# H3 register map
Vendor: Allwinner; Series: H3; File version: 0.1
CPU: 0, little endian, MPU, no FPU, 0 interrupt priority bits
Registers are 32-bit, read-write, reset 0x0 unless marked. A register's access mark holds for its fields unless they carry their own. Offsets are from the block's base; [hi:lo] are bit positions; lines under a group give offsets from that group; {n}, {i} and the like mark numbered series; 'fields as' and 'values as' point back to an identical list; <NAME> marks a mode.

## AC
Base 0x01C22C00
0x00 AC group
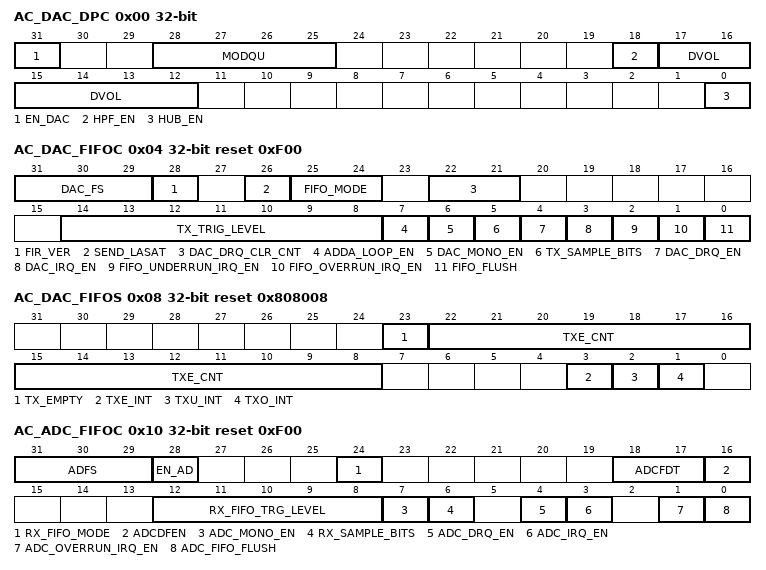
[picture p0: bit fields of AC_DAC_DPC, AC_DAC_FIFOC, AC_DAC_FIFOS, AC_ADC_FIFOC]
  0x00 AC_DAC_DPC — DAC Digital Part Control Register
    [31] EN_DAC — DAC Digital Part Enable 0 : Disable 1 : Enable
    [28:25] MODQU — Internal DAC Quantization Levels Levels=[7*(21+MODQU[3:0])]/128 Default levels=7*21/128=1.15
    [18] HPF_EN — High Pass Filter Enable 0: Disable 1: Enable
      0=Disable; 1=Enable
    [17:12] DVOL — Digital volume control: DVC, ATT=DVC[5:0]*(-1.16Db) 64 steps, -1.16Db/step
    [0] HUB_EN — Audio Hub Enable 0: Disable 1: Enable
      0=Disable; 1=Enable
  0x04 AC_DAC_FIFOC reset 0xF00 — DAC FIFO Control Register
    [31:29] DAC_FS — Sample Rate Of DAC 000: 48KHz 010: 24KHz 100: 12KHz 110: 192KHz 001: 32KHz 011: 16KHz 101: 8KHz 111: 96KHz 44.1KHz/22.05KHz/11.025KHz can be supported by Audio PLL Configure Bit
      0=_48KHz; 2=_24KHz; 4=_12KHz; 6=_192KHz; 1=_32KHz; 3=_16KHz; 5=_8KHz; 7=96KHz 44.1KHz/22.05KHz/11.025KHz can be supported by Audio PLL Configure Bit
    [28] FIR_VER — FIR Version 0: 64-Tap FIR; 1: 32-Tap FIR
      0=_64_minus_Tap (64-Tap FIR; 1: 32-Tap FIR)
    [26] SEND_LASAT — Audio sample select when TX FIFO under run 0: Sending zero 1: Sending last audio sample
      0=Sending_zero; 1=Sending last audio sample
    [25:24] FIFO_MODE — For 24-bits transmitted audio sample: 00/10: FIFO_I[23:0] = {TXDATA[31:8]} 01/11: Reserved For 16-bits transmitted audio sample: 00/10: FIFO_I[23:0] = {TXDATA[31:16], 8`b0} 01/11: FIFO_I[23:0] = {TXDATA[15:0], 8`b0}
    [22:21] DAC_DRQ_CLR_CNT — When TX FIFO Available Room Less Than Or Equal N, DRQ Request Will Be De-Asserted. N Is Defined Here: 00: IRQ/DRQ De-Asserted When WLEVEL > TXTL 01: 4 10: 8 11: 16
      0=IRQ_slash_DRQ (IRQ/DRQ De-Asserted When WLEVEL > TXTL); 1=_4; 2=_8; 3=_16
    [14:8] TX_TRIG_LEVEL — TX FIFO Empty Trigger Level (TXTL[12:0]) Interrupt and DMA request trigger level for TX FIFO normal condition. IRQ/DRQ Generated when WLEVEL <= TXTL Notes: 1. WLEVEL represents the number of valid samples in the TX FIFO 2. Only TXTL[6:0] valid when TXMODE = 0
    [7] ADDA_LOOP_EN — ADDA Loop Enable 0: Disable 1: Enable
      0=Disable; 1=Enable
    [6] DAC_MONO_EN — DAC Mono Enable 0: Stereo, 64 Levels FIFO 1: Mono, 128 Levels FIFO When Enabled, L & R Channel Send Same Data
      0=Stereo, 64 Levels FIFO; 1=Mono, 128 Levels FIFO When Enabled, L & R Channel Send Same Data
    [5] TX_SAMPLE_BITS — Transmitting Audio Sample Resolution 0: 16 bits 1: 24 bits
      0=_16_bits; 1=_24_bits
    [4] DAC_DRQ_EN — DAC FIFO Empty DRQ Enable 0: Disable 1: Enable
      0=Disable; 1=Enable
    [3] DAC_IRQ_EN — DAC FIFO Empty IRQ Enable 0: Disable 1: Enable
      0=Disable; 1=Enable
    [2] FIFO_UNDERRUN_IRQ_EN — DAC FIFO Under Run IRQ Enable 0: Disable 1: Enable
      0=Disable; 1=Enable
    [1] FIFO_OVERRUN_IRQ_EN — DAC FIFO Over Run IRQ Enable 0: Disable 1: Enable
      0=Disable; 1=Enable
    [0] FIFO_FLUSH — DAC FIFO Flush Write `1` To Flush TX FIFO, Self Clear to `0`
  0x08 AC_DAC_FIFOS reset 0x808008 — DAC FIFO Status Register
    [23] TX_EMPTY ro — TX FIFO Empty 0: No room for new sample in TX FIFO 1: More than one room for new sample in TX FIFO (>= 1 word)
      0=No room for new sample in TX FIFO; 1=More than one room for new sample in TX FIFO (>= 1 word)
    [22:8] TXE_CNT ro — TX FIFO Empty Space Word Counter
    [3] TXE_INT — TX FIFO Empty Pending Interrupt 0: No Pending IRQ 1: FIFO Empty Pending Interrupt Write `1` to clear this interrupt or automatic clear if interrupt condition fails
      0=No Pending IRQ; 1=FIFO (FIFO Empty Pending Interrupt Write `1` to clear this interrupt or automatic clear if interrupt condition fails)
    [2] TXU_INT — TX FIFO Under run Pending Interrupt 0: No Pending Interrupt 1: FIFO Under run Pending Interrupt Write `1` to clear this interrupt
      0=No Pending Interrupt; 1=FIFO (FIFO Under run Pending Interrupt Write `1` to clear this interrupt)
    [1] TXO_INT — TX FIFO Overrun Pending Interrupt 0: No Pending Interrupt 1: FIFO Overrun Pending Interrupt Write `1` to clear this interrupt
      0=No Pending Interrupt; 1=FIFO (FIFO Overrun Pending Interrupt Write `1` to clear this interrupt)
  0x10 AC_ADC_FIFOC reset 0xF00 — ADC FIFO Control Register
    [31:29] ADFS — Sample Rate of ADC 000: 48KHz 010: 24KHz 100: 12KHz 110: Reserved 001: 32KHz 011: 16KHz 101: 8KHz 111: Reserved 44.1KHz/22.05KHz/11.025KHz can be supported by Audio PLL Configure Bit
      0=_48KHz; 2=_24KHz; 4=_12KHz; 1=_32KHz; 3=_16KHz; 5=_8KHz
    [28] EN_AD — ADC Digital Part Enable 0: Disable 1: Enable :25 / / /
      0=Disable; 1=Enable :25 / / /
    [24] RX_FIFO_MODE — RX FIFO Output Mode (Mode 0, 1) 0: Expanding `0` at LSB of TX FIFO register 1: Expanding received sample sign bit at MSB of TX FIFO register For 24-bits received audio sample: Mode 0: RXDATA[31:0] = {FIFO_O[23:0], 8`h0} Mode 1: Reserved For 16-bits received audio sample: Mode 0: RXDATA[31:0] = {FIFO_O[23:8], 16`h0} Mode 1: RXDATA[31:0] = {16{FIFO_O[23]}, FIFO_O[23:8]}
      0=Expanding `0` at LSB of TX FIFO register; 1=Expanding received sample sign bit at MSB of TX FIFO register For 24-bits received audio sample: Mode 0: RXDATA[31:0] = {FIFO_O[23:0], 8`h0} Mode 1: Reserved For 16-bits received audio sample: Mode 0: RXDATA[31:0] = {FIFO_O[23:8], 16`h0} Mode 1: RXDATA[31:0] = {16{FIFO_O[23]}, FIFO_O[23:8]}
    [18:17] ADCFDT — ADC FIFO Delay Time For writing Data after EN_AD 00:5ms 01:10ms 10:20ms 11:30ms
    [16] ADCDFEN — ADC FIFO Delay Function For writing Data after EN_AD 0: Disable 1: Enable
      0=Disable; 1=Enable
    [12:8] RX_FIFO_TRG_LEVEL — RX FIFO Trigger Level (RXTL[4:0]) Interrupt and DMA request trigger level for RX FIFO normal condition IRQ/DRQ Generated when WLEVEL < RXTL[4:0] Notes: WLEVEL represents the number of valid samples in the RX FIFO
    [7] ADC_MONO_EN — ADC Mono Enable 0: Stereo, 16 levels FIFO 1: mono, 32 levels FIFO When set to `1`, Only left channel samples are recorded
      0=Stereo, 16 levels FIFO; 1=mono, 32 levels FIFO When set to `1`, Only left channel samples are recorded
    [6] RX_SAMPLE_BITS — Receiving Audio Sample Resolution 0: 16 bits 1: 24 bits
      0=_16_bits; 1=_24_bits
    [4] ADC_DRQ_EN — ADC FIFO Data Available DRQ Enable 0: Disable 1: Enable
      0=Disable; 1=Enable
    [3] ADC_IRQ_EN — ADC FIFO Data Available IRQ Enable 0: Disable 1: Enable
      0=Disable; 1=Enable
    [1] ADC_OVERRUN_IRQ_EN — ADC FIFO Over Run IRQ Enable 0: Disable 1: Enable
      0=Disable; 1=Enable
    [0] ADC_FIFO_FLUSH — ADC FIFO Flush Write `1` to flush TX FIFO, self clear to `0`
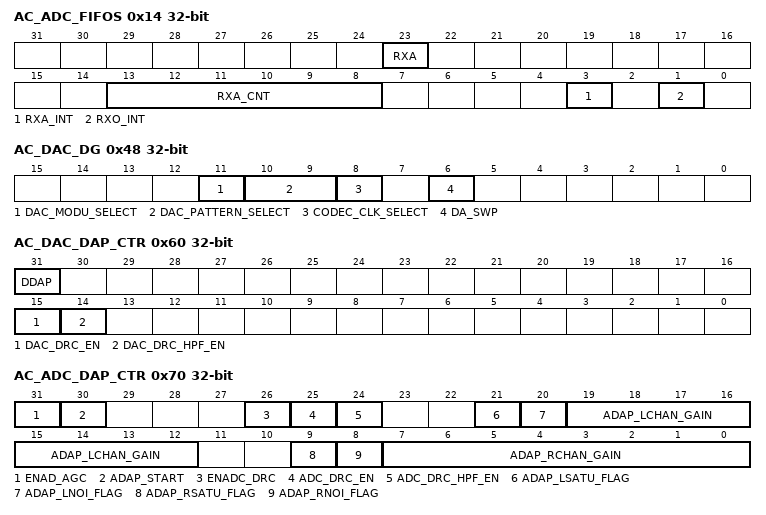
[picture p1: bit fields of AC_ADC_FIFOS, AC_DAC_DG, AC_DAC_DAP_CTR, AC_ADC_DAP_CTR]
  0x14 AC_ADC_FIFOS — ADC FIFO Status Register
    [23] RXA ro — RX FIFO Available 0: No available data in RX FIFO 1: More than one sample in RX FIFO (>= 1 word)
      0=No available data in RX FIFO; 1=More than one sample in RX FIFO (>= 1 word)
    [13:8] RXA_CNT ro — RX FIFO Available Sample Word Counter
    [3] RXA_INT — RX FIFO Data Available Pending Interrupt 0: No Pending IRQ 1: Data Available Pending IRQ Write `1` to clear this interrupt or automatic clear if interrupt condition fails
      0=No Pending IRQ; 1=Data Available Pending IRQ Write `1` to clear this interrupt or automatic clear if interrupt condition fails
    [1] RXO_INT — RX FIFO Overrun Pending Interrupt 0: No Pending IRQ 1: FIFO Overrun Pending IRQ Write `1` to clear this interrupt
      0=No Pending IRQ; 1=FIFO (FIFO Overrun Pending IRQ Write `1` to clear this interrupt)
  0x18 AC_ADC_RXDATA — ADC RX Data Register
    [31:0] RX_DATA ro — RX Sample Host can get one sample by reading this register. The left channel sample data is first and then the right channel sample.
  0x20 AC_DAC_TXDATA — DAC TX Data Register
    [31:0] TX_DATA wo — Transmitting left, right channel sample data should be written this register one by one. The left channel sample data is first and then the right channel sample
  0x40 AC_DAC_CNT — DAC TX FIFO Counter Register
    [31:0] TX_CNT — TX Sample Counter The audio sample number of sending into TXFIFO. When one sample is put into TXFIFO by DMA or by host IO, the TX sample counter register increases by one. The TX sample counter register can be set to any initial valve at any time. After been updated by the initial value, the counter register should count on base of this initial value Notes: It is used for Audio/ Video Synchronization
  0x44 AC_ADC_CNT — ADC RX FIFO Counter Register
    [31:0] RX_CNT — RX Sample Counter The audio sample number of writing into RXFIFO. When one sample is written by Digital Audio Engine, the RX sample counter register increases by one. The RX sample counter register can be set to any initial valve at any time. After been updated by the initial value, the counter register should count on base of this initial value Notes: It is used for Audio/ Video Synchronization
  0x48 AC_DAC_DG — DAC Debug Register
    [11] DAC_MODU_SELECT — DAC Modulator Debug 0: DAC Modulator Normal Mode 1: DAC Modulator Debug Mode
      0=DAC Modulator Normal Mode; 1=DAC Modulator Debug Mode
    [10:9] DAC_PATTERN_SELECT — DAC Pattern Select 00: Normal (Audio Sample from TX FIFO) 01: -6 dB Sin wave 10: -60 dB Sin wave 11: silent wave
      0=Normal (Audio Sample from TX FIFO); 1=_minus_6_dB (-6 dB Sin wave); 2=_minus_60_dB (-60 dB Sin wave); 3=silent wave
    [8] CODEC_CLK_SELECT — CODEC Clock Source Select 0: CODEC Clock from PLL 1: CODEC Clock from OSC (For Debug)
      0=CODEC_Clock_from_PLL; 1=CODEC Clock from OSC (For Debug)
    [6] DA_SWP — DAC output channel swap enable 0:Disable 1:Enable
  0x4C AC_ADC_DG — ADC Debug Register
    [24] AD_SWP — ADC Output Channel Swap Enable (for digital filter) 0: Disable 1: Enable
      0=Disable; 1=Enable
  0x60 AC_DAC_DAP_CTR — DAC DAP Control Register
    [31] DDAP — _EN DAP for dac Enable 0 : bypass 1 : enable
    [15] DAC_DRC_EN — DRC enable control 0:disable 1:enable
    [14] DAC_DRC_HPF_EN — HPF enable control 0:disable 1:enable
  0x70 AC_ADC_DAP_CTR — ADC DAP Control Register
    [31] ENAD_AGC — AGC for ADC enable 0 : bypass 1: enable
    [30] ADAP_START — DAP for ADC start up 0 : disable 1: start up
      1=start up
    [26] ENADC_DRC — DRC for ADC enable 0 : bypass 1 : enable
    [25] ADC_DRC_EN — ADC DRC function enable
    [24] ADC_DRC_HPF_EN — ADC DRC HPF function enable
    [21] ADAP_LSATU_FLAG ro — Left channel AGC saturation flag 0 : no saturation 1: saturation
      1=saturation
    [20] ADAP_LNOI_FLAG ro — Left channel AGC noise-threshold flag 0: no noise-threshold 1: noise-threshold
      0=no_noise_minus_threshold (no noise-threshold); 1=noise_minus_threshold (noise-threshold)
    [19:12] ADAP_LCHAN_GAIN ro — Left channel Gain applied by AGC (7.1format 2s component(-20dB 40dB), 0.5dB/ step) 0x50 : 40dB 0x4F : 39.5dB --------------- 0x00 : 00dB 0xFF : -0.5dB
    [9] ADAP_RSATU_FLAG ro — Right AGC saturation flag 0 : no saturation 1: saturation
      1=saturation
    [8] ADAP_RNOI_FLAG ro — Right channel AGC noise-threshold flag 0: 1:
      0=0b0; 1=0b1
    [7:0] ADAP_RCHAN_GAIN ro — Right Channel Gain applied by AGC (7.1format 2s component)(0.5dB step 0x50 : 40dB 0x4F : 39.5dB --------------- 0x00 : 00dB 0xFF : -0.5dB
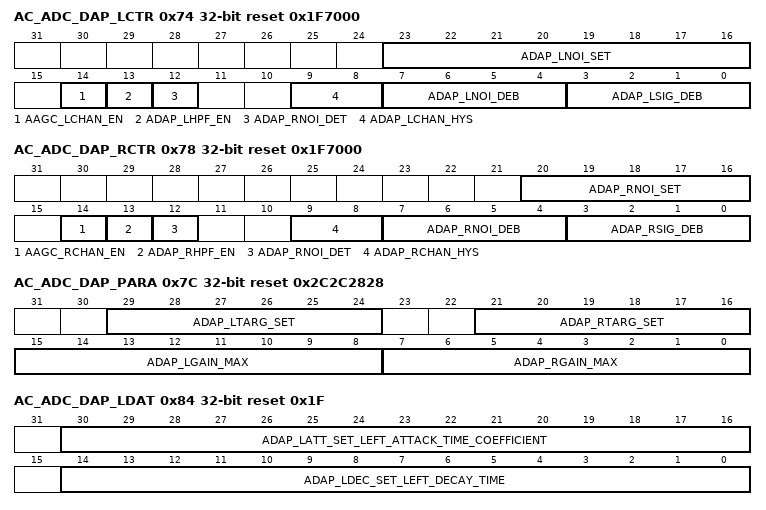
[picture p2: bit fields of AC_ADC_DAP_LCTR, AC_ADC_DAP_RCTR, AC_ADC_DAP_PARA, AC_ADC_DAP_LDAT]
  0x74 AC_ADC_DAP_LCTR reset 0x1F7000 — ADC DAP Left Control Register
    [23:16] ADAP_LNOI_SET — (-86dB) ADAP_LNOI_SET. Left channel noise threshold setting 0x00 : -24dB 0x01 : -26dB 0x02 : -28dB ---------------------- 0x1D: -82dB 0x1E: -84dB 0x1F: -86dB
      29=_minus_82dB (-82dB); 30=_minus_84dB (-84dB); 31=_minus_86dB (-86dB)
    [14] AAGC_LCHAN_EN — AAGC_LCHAN_EN. Left AGC function enable 0:disable 1: enable
      1=enable
    [13] ADAP_LHPF_EN — ADAP_LHPF_EN. Left HPF enable 0: disable 1: enable
      0=disable; 1=enable
    [12] ADAP_RNOI_DET — ADAP_RNOI_DET. Left Noise detect enable 0: disable 1:enable
      0=disable; 1=enable
    [9:8] ADAP_LCHAN_HYS — ADAP_LCHAN_HYS. Left Hysteresis setting 00 : 1dB 01 : 2dB 10 : 4dB 11 : disable
    [7:4] ADAP_LNOI_DEB — ADAP_LNOI_DEB. Left Noise debounce time 0000:0/fs 0001:4/fs 0010:8/fs ------------ 1111 :16*4096/fs T=2(N+1)/fs ,except N=0
    [3:0] ADAP_LSIG_DEB — ADAP_LSIG_DEB. Left Signal debounce time 0000:0/fs 0001:4/fs 0010:8/fs ------------ 1111 :16*4096/fs T=2(N+1)/fs ,except N=0
  0x78 AC_ADC_DAP_RCTR reset 0x1F7000 — ADC DAP Right Control Register
    [20:16] ADAP_RNOI_SET — (-86dB) ADAP_RNOI_SET. Right channel noise threshold setting 0x00 : -24dB 0x01 : -26dB 0x02 : -28dB ---------------------- 0x1D: -82dB 0x1E: -84dB 0x1F: -86dB
      values as AC.AC_ADC_DAP_LCTR.ADAP_LNOI_SET
    [14] AAGC_RCHAN_EN — AAGC_RCHAN_EN. Right AGC enable 0:disable 1:enable
    [13] ADAP_RHPF_EN — ADAP_RHPF_EN. Right HPF enable 0: disable 1: enable
      0=disable; 1=enable
    [12] ADAP_RNOI_DET — ADAP_RNOI_DET. Right Noise detect enable 0: disable 1:enable
      0=disable; 1=enable
    [9:8] ADAP_RCHAN_HYS — ADAP_RCHAN_HYS. Right Hysteresis setting 00 : 1dB 01 : 2dB 10 : 4dB 11 : disable;
    [7:4] ADAP_RNOI_DEB — ADAP_RNOI_DEB. Right Noise debounce time 0000:0/fs 0001:4/fs 0010:8/fs ------------ 1111 16*4096/fs T=2(N+1)/fs ,except N=0
    [3:0] ADAP_RSIG_DEB — ADAP_RSIG_DEB. Right Signal debounce time 0000:0/fs 0001:4/fs 0010:8/fs ------------ 1111 16*4096/fs T=2(N+1)/fs ,except N=0
  0x7C AC_ADC_DAP_PARA reset 0x2C2C2828 — ADC DAP Parameter Register
    [29:24] ADAP_LTARG_SET — Left channel target level setting (-1dB -- -30dB). (6.0format 2s component)
    [21:16] ADAP_RTARG_SET — Right channel target level setting (-1dB -- -30dB). (6.0format 2s component)
    [15:8] ADAP_LGAIN_MAX — Left channel max gain setting (0-40dB). (7.1format 2s component)
    [7:0] ADAP_RGAIN_MAX — Right channel max gain setting (0-40dB). (7.1format 2s component)
  0x80 AC_ADC_DAP_LAC reset 0x51EB8 — ADC DAP Left Average Coef Register
    [26:0] ADAP_LAC — Average level coefficient setting(3.24format 2s component)
  0x84 AC_ADC_DAP_LDAT reset 0x1F — ADC DAP Left Decay and Attack Time Register
    [30:16] ADAP_LATT_SET_LEFT_ATTACK_TIME_COEFFICIENT — ADAP_LATT_SET Left attack time coefficient setting 0000 : 1x32/fs 0001 : 2x32/fs ------------------------ 7FFF : 215 x32/fs T=(n+1)*32*fs When the gain decreases, the actual gain will decrease 0.5dB at every attack time.
    [14:0] ADAP_LDEC_SET_LEFT_DECAY_TIME — (32x32fs) ADAP_LDEC_SET Left decay time coefficient setting 0000 : 1x32/fs 0001 : 2x32/fs ------------------------ 7FFF : 215 x32/fs T=(n+1)*32/fs When the gain increases, the actual gain will increase 0.5dB at every decay time.
  0x88 AC_ADC_DAP_RAC reset 0x51EB8 — ADC DAP Right Average Coef Register
    [26:0] ADAP_RAC — Average level coefficient setting(3.24fomat)
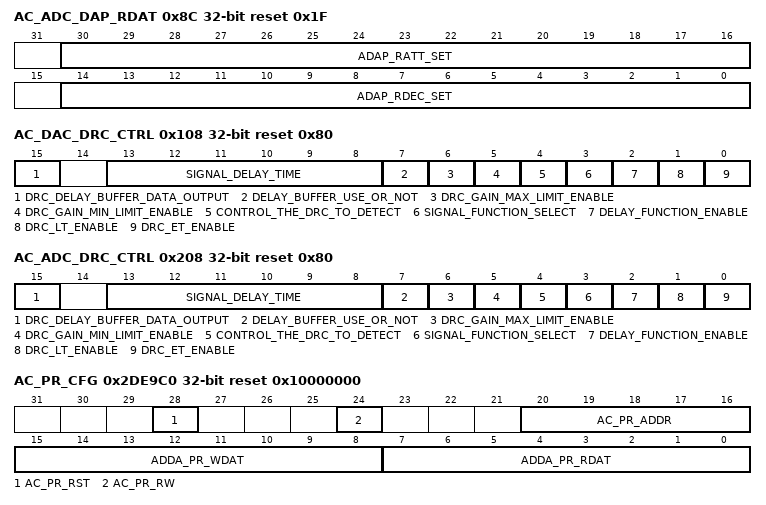
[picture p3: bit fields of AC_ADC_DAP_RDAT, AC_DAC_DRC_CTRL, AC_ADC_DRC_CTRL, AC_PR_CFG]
  0x8C AC_ADC_DAP_RDAT reset 0x1F — ADC DAP Right Decay and Attack Time Register
    [30:16] ADAP_RATT_SET — Right attack time coefficient setting 0000 : 1x32/fs 0001 : 2x32/fs ------------------------ 7FFF : 215 x32/fs T=(n+1)*32/fs When the gain decreases, the actual gain will decrease 0.5dB at every attack time.
    [14:0] ADAP_RDEC_SET — Right decay time coefficient setting 0000 : 1x32/fs 0001 : 2x32/fs ------------------------ 7FFF : 215x32/fs T=(n+1)*32/fs When the gain increases, the actual gain will increase 0.5dB at every decay time.
  0x90 AC_ADC_DAP_HPFC reset 0xFFFAC1 — ADC DAP HPF Coef Register
    [26:0] ADAP_HPFC — HPF coefficient setting (3.24fomat)
  0x94 AC_ADC_DAP_LINAC reset 0x51EB8 — ADC DAP Left Input Signal Low Average Coef Register
    [26:0] ADAP_LINAC — Left input signal average filter coefficient to check noise or not (the coefficientis 3.24 format 2s complement) always the same as the left output signal average filter's
  0x100 AC_DAC_DRC_HHPFC reset 0xFF — DAC DRC High HPF Coef Register
    [10:0] HPF — coefficient setting and the data is 3.24 format.
  0x104 AC_DAC_DRC_LHPFC reset 0xFAC1 — DAC DRC Low HPF Coef Register
    [15:0] HPF — coefficient setting and the data is 3.24 format.
  0x108 AC_DAC_DRC_CTRL reset 0x80 — DAC DRC Control Register
    [15] DRC_DELAY_BUFFER_DATA_OUTPUT ro — DRC delay buffer data output state when drc delay function is enble and the drc funciton disable. After disable drc function and this bit go to 0, the user should write the drc delay function bit to 0; 0 : not complete 1 : is complete
    [13:8] SIGNAL_DELAY_TIME — Signal delay time setting 6'h00 : (8x1)fs 6'h01 : (8x2)fs 6'h02 : (8x3)fs ---------------------------------------- 6'h2e : (8*47)fs 6'h2f : (8*48)fs 6'h30 -- 6'h3f : (8*48)fs Delay time = 8*(n+1)fs, n<6'h30; When the delay function is disable, the signal delay time is unused.
    [7] DELAY_BUFFER_USE_OR_NOT — The delay buffer use or not when the drc disable and the drc buffer data output completely 0 : don't use the buffer 1 : use the buffer
    [6] DRC_GAIN_MAX_LIMIT_ENABLE — DRC gain max limit enable 0 : disable 1 : enable
    [5] DRC_GAIN_MIN_LIMIT_ENABLE — DRC gain min limit enable. when this function enable, it will overwrite the noise detect function. 0 : disable 1 : enable
    [4] CONTROL_THE_DRC_TO_DETECT — Control the drc to detect noise when ET enable 0 : disable 1 : enable
    [3] SIGNAL_FUNCTION_SELECT — Signal function Select 0 : RMS filter 1 : Peak filter When Signal function Select Peak filter, the RMS parameter is unused. (AC_DRC_LRMSHAT / AC_DRC_LRMSLAT / AC_DRC_LRMSHAT / AC_DRC_LRMSLAT) When Signal function Select RMS filter, the Peak filter parameter is unused.(AC_DRC_LPFHAT / AC_DRC_LPFLAT / AC_DRC_RPFHAT / AC_DRC_RPFLAT / AC_DRC_LPFHRT / AC_DRC_LPFLRT / AC_DRC_RPFHRT / AC_DRC_RPFLRT)
    [2] DELAY_FUNCTION_ENABLE — Delay function enable 0 : disable 1 : enable When the Delay function enable is disable, the Signal delay time is unused.
    [1] DRC_LT_ENABLE — DRC LT enable 0 : disable 1 : enable When the DRC LT is disable the LT, Kl and OPL parameter is unused.
    [0] DRC_ET_ENABLE — DRC ET enable 0 : disable 1 : enable When the DRC ET is disable the ET, Ke and OPE parameter is unused.
  0x10C AC_DAC_DRC_LPFHAT reset 0xB — DAC DRC Left Peak Filter High Attack Time Coef Register
    [10:0] LEFT_PEAK_FILTER_ATTACK_TIME — The left peak filter attack time parameter setting, which determine by the equation that AT = 1-exp(-2.2Ts/ta). The format is 3.24. (1ms)
  0x110 AC_DAC_DRC_LPFLAT reset 0x77BF — DAC DRC Left Peak Filter Low Attack Time Coef Register
    [15:0] LEFT_PEAK_FILTER_ATTACK_TIME — The left peak filter attack time parameter setting, which determine by the equation that AT = 1-exp(-2.2Ts/ta). The format is 3.24. (1ms)
  0x114 AC_DAC_DRC_RPFHAT reset 0xB — DAC DRC Right Peak Filter High Attack Time Coef Register
    fields as AC.AC_DAC_DRC_LPFHAT
  0x118 AC_DAC_DRC_RPFLAT reset 0x77BF — DAC DRC Peak Filter Low Attack Time Coef Register
    fields as AC.AC_DAC_DRC_LPFLAT
  0x11C AC_DAC_DRC_LPFHRT reset 0xFF — DAC DRC Left Peak Filter High Release Time Coef Register
    [10:0] LEFT_PEAK_FILTER_RELEASE_TIME — The left peak filter release time parameter setting, which determine by the equation that RT = exp(-2.2Ts/tr). The format is 3.24. (100ms)
  0x120 AC_DAC_DRC_LPFLRT reset 0xE1F8 — DAC DRC Left Peak Filter Low Release Time Coef Register
    [15:0] LEFT_PEAK_FILTER_RELEASE_TIME — The left peak filter release time parameter setting, which determine by the equation that RT = exp(-2.2Ts/tr). The format is 3.24. (100ms)
  0x124 AC_DAC_DRC_RPFHRT reset 0xFF — DAC DRC Right Peak filter High Release Time Coef Register
    [10:0] LEFT_PEAK_FILTER_ATTACK_TIME — The left peak filter attack time parameter setting, which determine by the equation that RT = exp(-2.2Ts/tr). The format is 3.24. (100ms)
  0x128 AC_DAC_DRC_RPFLRT reset 0xE1F8 — DAC DRC Right Peak filter Low Release Time Coef Register
    [15:0] LEFT_PEAK_FILTER_RELEASE_TIME — The left peak filter release time parameter setting, which determine by the equation that AT = exp(-2.2Ts/tr). The format is 3.24. (100ms)
  0x12C AC_DAC_DRC_LRMSHAT reset 0x1 — DAC DRC Left RMS Filter High Coef Register
    [10:0] LEFT_RMS_FILTER_AVERAGE_TIME — The left RMS filter average time parameter setting, which determine by the equation that AT = 1-exp(-2.2Ts/tav). The format is 3.24. (10ms)
  0x130 AC_DAC_DRC_LRMSLAT reset 0x2BAF — DAC DRC Left RMS Filter Low Coef Register
    [15:0] LEFT_RMS_FILTER_AVERAGE_TIME — The left RMS filter average time parameter setting, which determine by the equation that AT = 1-exp(-2.2Ts/tav). The format is 3.24. (10ms)
  0x134 AC_DAC_DRC_RRMSHAT reset 0x1 — DAC DRC Right RMS Filter High Coef Register
    [10:0] RIGHT_RMS_FILTER_AVERAGE_TIME — The right RMS filter average time parameter setting, which determine by the equation that AT = 1-exp(-2.2Ts/tav). The format is 3.24. (10ms)
  0x138 AC_DAC_DRC_RRMSLAT reset 0x2BAF — DAC DRC Right RMS Filter Low Coef Register
    [15:0] RIGHT_RMS_FILTER_AVERAGE_TIME — The right RMS filter average time parameter setting, which determine by the equation that AT = 1-exp(-2.2Ts/tav). The format is 3.24. (10ms)
  0x13C AC_DAC_DRC_HCT reset 0x6A4 — DAC DRC Compressor Theshold High Setting Register
    [15:0] COMPRESSOR_THRESHOLD — The compressor threshold setting, which set by the equation that CTin = -CT/6.0206. The format is 8.24 (-40dB)
  0x140 AC_DAC_DRC_LCT reset 0xD3C0 — DAC DRC Compressor Slope High Setting Register
    fields as AC.AC_DAC_DRC_HCT
  0x144 AC_DAC_DRC_HKC reset 0x80 — DAC DRC Compressor Slope High Setting Register
    [13:0] COMPRESSOR_SLOPE — The slope of the compressor which determine by the equation that Kc = 1/R, there, R is the ratio of the compressor, which always is interger. The format is 8.24. (2 : 1)
  0x148 AC_DAC_DRC_LKC — DAC DRC Compressor Slope Low Setting Register
    [15:0] COMPRESSOR_SLOPE — The slope of the compressor which determine by the equation that Kc = 1/R, there, R is the ratio of the compressor, which always is interger. The format is 8.24. (2 : 1)
  0x14C AC_DAC_DRC_HOPC reset 0xF95B — DAC DRC Compressor High Output at Compressor Threshold Register
    [15:0] COMPRESSOR_OUTPUT — The output of the compressor which determine by the equation -OPC/6.0206 The format is 8.24 (-40dB)
  0x150 AC_DAC_DRC_LOPC reset 0x2C3F — DAC DRC Compressor Low Output at Compressor Threshold Register
    [15:0] COMPRESSOR_OUTPUT — The output of the compressor which determine by the equation OPC/6.0206 The format is 8.24 (-40dB)
  0x154 AC_DAC_DRC_HLT reset 0x1A9 — DAC DRC Limiter Theshold High Setting Register
    [15:0] LIMITER_THRESHOLD — The limiter threshold setting, which set by the equation that LTin = -LT/6.0206, The format is 8.24. (-10dB)
  0x158 AC_DAC_DRC_LLT reset 0x34F0 — DAC DRC Limiter Theshold Low Setting Register
    fields as AC.AC_DAC_DRC_HLT
  0x15C AC_DAC_DRC_HKl reset 0x5 — DAC DRC Limiter Slope High Setting Register
    [13:0] LIMITER_SLOPE — The slope of the limiter which determine by the equation that Kl = 1/R, there, R is the ratio of the limiter, which always is interger. The format is 8.24. (50 :1)
  0x160 AC_DAC_DRC_LKl reset 0x1EB8 — DAC DRC Limiter Slope Low Setting Register
    [15:0] LIMITER_SLOPE — The slope of the limiter which determine by the equation that Kl = 1/R, there, R is the ratio of the limiter, which always is interger. The format is 8.24. (50 :1)
  0x164 AC_DAC_DRC_HOPL reset 0xFBD8 — DAC DRC Limiter High Output at Limiter Threshold
    [15:0] LIMITER_OUTPUT — The output of the limiter which determine by equation OPT/6.0206. The format is 8.24 (-25dB)
  0x168 AC_DAC_DRC_LOPL reset 0xFBA7 — DAC DRC Limiter Low Output at Limiter Threshold
    fields as AC.AC_DAC_DRC_HOPL
  0x16C AC_DAC_DRC_HET reset 0xBA0 — DAC DRC Expander Theshold High Setting Register
    [15:0] EXPANDER_THRESHOLD — The expander threshold setting, which set by the equation that ETin = -ET/6.0206, The format is 8.24. (-70dB)
  0x170 AC_DAC_DRC_LET reset 0x7291 — DAC DRC Expander Theshold Low Setting Register
    fields as AC.AC_DAC_DRC_HET
  0x174 AC_DAC_DRC_HKE reset 0x500 — DAC DRC Expander Slope High Setting Register
    [13:0] EXPANDER_WHICH_DETERMINE_SLOPE — The slope of the expander which determine by the equation that Ke = 1/R, there, R is the ratio of the expander, which always is interger and the ke must larger than 50. The format is 8.24. (1:5)
  0x178 AC_DAC_DRC_LKE — DAC DRC Expander Slope Low Setting Register
    [15:0] EXPANDER_SLOPE — The slope of the expander which determine by the equation that Ke = 1/R, there, R is the ratio of the expander, which always is interger and the ke must larger than 50. The format is 8.24. (1:5)
  0x17C AC_DAC_DRC_HOPE reset 0xF45F — DAC DRC Expander High Output at Expander Threshold
    [15:0] EXPANDER_OUTPUT — The output of the expander which determine by equation OPE/6.0206. The format is 8.24 (-70dB)
  0x180 AC_DAC_DRC_LOPE reset 0x8D6E — DAC DRC Expander Low Output at Expander Threshold
    fields as AC.AC_DAC_DRC_HOPE
  0x184 AC_DAC_DRC_HKN reset 0x100 — DAC DRC Linear Slope High Setting Register
    [13:0] LINEAR_SLOPE — The slope of the linear which determine by the equation that Kn = 1/R, there, R is the ratio of the linear, which always is interger . The format is 8.24. (1:1)
  0x188 AC_DAC_DRC_LKN — DAC DRC Linear Slope Low Setting Register
    [15:0] LINEAR_SLOPE — The slope of the linear which determine by the equation that Kn = 1/R, there, R is the ratio of the linear, which always is interger . The format is 8.24. (1:1)
  0x18C AC_DAC_DRC_SFHAT reset 0x2 — DAC DRC Smooth filter Gain High Attack Time Coef Register
    [10:0] SMOOTH_FILTER_ATTACK_TIME — The smooth filter attack time parameter setting, which determine by the equation that AT = 1-exp(-2.2Ts/tr). The format is 3.24. (5ms)
  0x190 AC_DAC_DRC_SFLAT reset 0x5600 — DAC DRC Smooth filter Gain Low Attack Time Coef Register
    [15:0] SMOOTH_FILTER_ATTACK_TIME — The smooth filter attack time parameter setting, which determine by the equation that AT = 1-exp(-2.2Ts/tr). The format is 3.24. (5ms)
  0x194 AC_DAC_DRC_SFHRT — DAC DRC Smooth filter Gain High Release Time Coef Register
    [10:0] GAIN_SMOOTH_FILTER_RELEASE_TIME — The gain smooth filter release time parameter setting, which determine by the equation that RT = 1-exp(-2.2Ts/tr). The format is 3.24. (200ms)
  0x198 AC_DAC_DRC_SFLRT reset 0xF04 — DAC DRC Smooth filter Gain Low Release Time Coef Register
    [15:0] GAIN_SMOOTH_FILTER_RELEASE_TIME — The gain smooth filter release time parameter setting, which determine by the equation that RT = 1-exp(-2.2Ts/tr). The format is 3.24. (200ms)
  0x19C AC_DAC_DRC_MXGHS reset 0xFE56 — DAC DRC MAX Gain High Setting Register
    [15:0] MAX_GAIN — The max gain setting which determine by equation MXG/6.0206. The format is 8.24 and must -20dB <MXG< 30dB (-10dB)
  0x1A0 AC_DAC_DRC_MXGLS reset 0xCB0F — DAC DRC MAX Gain Low Setting Register
    [15:0] MAX_GAIN — The max gain setting which determine by equation MXG/6.0206. The format is 8.24 and must -20dB <MXG < 30dB (-10dB)
  0x1A4 AC_DAC_DRC_MNGHS reset 0xF95B — DAC DRC MIN Gain High Setting Register
    [15:0] MIN_GAIN — The min gain setting which determine by equation MXG/6.0206. The format is 8.24 and must -60dB MNG -30dB (-40dB)
  0x1A8 AC_DAC_DRC_MNGLS reset 0x2C3F — DAC DRC MIN Gain Low Setting Register
    [15:0] MIN_GAIN — The min gain setting which determine by equation MNG/6.0206. The format is 8.24 and must -60dB MNG -30dB (-40dB)
  0x1AC AC_DAC_DRC_EPSHC — DAC DRC Expander Smooth Time High Coef Register
    [11:0] GAIN_SMOOTH_FILTER_RELEASE — The gain smooth filter release and attack time parameter setting in expander region, which determine by the equation that RT = 1-exp(-2.2Ts/tr). The format is 3.24. (30ms)
  0x1B0 AC_DAC_DRC_EPSLC reset 0x640C — DAC DRC Expander Smooth Time Low Coef Register
    [15:0] GAIN_SMOOTH_FILTER_RELEASE — The gain smooth filter release and attack time parameter setting in expander region, which determine by the equation that RT = 1-exp(-2.2Ts/tr). The format is 3.24. (30ms)
  0x1B8 AC_DAC_DRC_HPFHGAIN reset 0x100 — DAC DRC HPF Gain High Coef Register
    [10:0] HPF_COEFFICIENT_GAIN — The gain of the hpf coefficient setting which format is 3.24.(gain = 1)
  0x1BC AC_DAC_DRC_HPFLGAIN — DAC DRC HPF Gain Low Coef Register
    [15:0] HPF_COEFFICIENT_GAIN — The gain of the hpf coefficient setting which format is 3.24.(gain = 1)
  0x200 AC_ADC_DRC_HHPFC reset 0xFF — ADC DRC High HPF Coef Register
    [10:0] HPF — coefficient setting and the data is 3.24 format.
  0x204 AC_ADC_DRC_LHPFC reset 0xFAC1 — ADC DRC Low HPF Coef Register
    [15:0] HPF — coefficient setting and the data is 3.24 format.
  0x208 AC_ADC_DRC_CTRL reset 0x80 — ADC DRC Control Register
    [15] DRC_DELAY_BUFFER_DATA_OUTPUT ro — DRC delay buffer data output state when drc delay function is enable and the drc function disable. After disable drc function and this bit go to 0, the user should write the drc delay function bit to 0; 0 : not complete 1 : is complete
    [13:8] SIGNAL_DELAY_TIME — Signal delay time setting 6'h00 : (8x1)fs 6'h01 : (8x2)fs 6'h02 : (8x3)fs ---------------------------------------- 6'h2e : (8*47)fs 6'h2f : (8*48)fs 6'h30 -- 6'h3f : (8*48)fs Delay time = 8*(n+1)fs, n<6'h30; When the delay function is disable, the signal delay time is unused.
    [7] DELAY_BUFFER_USE_OR_NOT — The delay buffer use or not when the drc disable and the drc buffer data output completely 0 : don't use the buffer 1 : use the buffer
    [6] DRC_GAIN_MAX_LIMIT_ENABLE — DRC gain max limit enable 0 : disable 1 : enable
    [5] DRC_GAIN_MIN_LIMIT_ENABLE — DRC gain min limit enable. when this function enable, it will overwrite the noise detect function. 0 : disable 1 : enable
    [4] CONTROL_THE_DRC_TO_DETECT — Control the drc to detect noise when ET enable 0 : disable 1 : enable
    [3] SIGNAL_FUNCTION_SELECT — Signal function Select 0 : RMS filter 1 : Peak filter When Signal function Select Peak filter, the RMS parameter is unused. (AC_DRC_LRMSHAT / AC_DRC_LRMSLAT / AC_DRC_LRMSHAT / AC_DRC_LRMSLAT) When Signal function Select RMS filter, the Peak filter parameter is unused.(AC_DRC_LPFHAT / AC_DRC_LPFLAT / AC_DRC_RPFHAT / AC_DRC_RPFLAT / AC_DRC_LPFHRT / AC_DRC_LPFLRT / AC_DRC_RPFHRT / AC_DRC_RPFLRT)
    [2] DELAY_FUNCTION_ENABLE — Delay function enable 0 : disable 1 : enable When the Delay function enable is disable, the Signal delay time is unused.
    [1] DRC_LT_ENABLE — DRC LT enable 0 : disable 1 : enable When the DRC LT is disable the LT, Kl and OPL parameter is unused.
    [0] DRC_ET_ENABLE — DRC ET enable 0 : disable 1 : enable When the DRC ET is disable the ET, Ke and OPE parameter is unused.
  0x20C AC_ADC_DRC_LPFHAT reset 0xB — ADC DRC Left Peak Filter High Attack Time Coef Register
    fields as AC.AC_DAC_DRC_LPFHAT
  0x210 AC_ADC_DRC_LPFLAT reset 0x77BF — ADC DRC Left Peak Filter Low Attack Time Coef Register
    fields as AC.AC_DAC_DRC_LPFLAT
  0x214 AC_ADC_DRC_RPFHAT reset 0xB — ADC DRC Right Peak Filter High Attack Time Coef Register
    fields as AC.AC_DAC_DRC_LPFHAT
  0x218 AC_ADC_DRC_RPFLAT reset 0x77BF — ADC DRC Peak Filter Low Attack Time Coef Register
    fields as AC.AC_DAC_DRC_LPFLAT
  0x21C AC_ADC_DRC_LPFHRT reset 0xFF — ADC DRC Left Peak Filter High Release Time Coef Register
    fields as AC.AC_DAC_DRC_LPFHRT
  0x220 AC_ADC_DRC_LPFLRT reset 0xE1F8 — ADC DRC Left Peak Filter Low Release Time Coef Register
    fields as AC.AC_DAC_DRC_LPFLRT
  0x224 AC_ADC_DRC_RPFHRT reset 0xFF — ADC DRC Right Peak filter High Release Time Coef Register
    fields as AC.AC_DAC_DRC_RPFHRT
  0x228 AC_ADC_DRC_RPFLRT reset 0xE1F8 — ADC DRC Right Peak filter Low Release Time Coef Register
    fields as AC.AC_DAC_DRC_RPFLRT
  0x22C AC_ADC_DRC_LRMSHAT reset 0x1 — ADC DRC Left RMS Filter High Coef Register
    fields as AC.AC_DAC_DRC_LRMSHAT
  0x230 AC_ADC_DRC_LRMSLAT reset 0x2BAF — ADC DRC Left RMS Filter Low Coef Register
    fields as AC.AC_DAC_DRC_LRMSLAT
  0x234 AC_ADC_DRC_RRMSHAT reset 0x1 — ADC DRC Right RMS Filter High Coef Register
    fields as AC.AC_DAC_DRC_RRMSHAT
  0x238 AC_ADC_DRC_RRMSLAT reset 0x2BAF — ADC DRC Right RMS Filter Low Coef Register
    fields as AC.AC_DAC_DRC_RRMSLAT
  0x23C AC_ADC_DRC_HCT reset 0x6A4 — ADC DRC Compressor Theshold High Setting Register
    fields as AC.AC_DAC_DRC_HCT
  0x240 AC_ADC_DRC_LCT reset 0xD3C0 — ADC DRC Compressor Slope High Setting Register
    fields as AC.AC_DAC_DRC_HCT
  0x244 AC_ADC_DRC_HKC reset 0x80 — ADC DRC Compressor Slope High Setting Register
    fields as AC.AC_DAC_DRC_HKC
  0x248 AC_ADC_DRC_LKC — ADC DRC Compressor Slope Low Setting Register
    fields as AC.AC_DAC_DRC_LKC
  0x24C AC_ADC_DRC_HOPC reset 0xF95B — ADC DRC Compressor High Output at Compressor Threshold Register
    fields as AC.AC_DAC_DRC_LOPC
  0x250 AC_ADC_DRC_LOPC reset 0x2C3F — ADC DRC Compressor Low Output at Compressor Threshold Register
    fields as AC.AC_DAC_DRC_LOPC
  0x254 AC_ADC_DRC_HLT reset 0x1A9 — ADC DRC Limiter Theshold High Setting Register
    fields as AC.AC_DAC_DRC_HLT
  0x258 AC_ADC_DRC_LLT reset 0x34F0 — ADC DRC Limiter Theshold Low Setting Register
    fields as AC.AC_DAC_DRC_HLT
  0x25C AC_ADC_DRC_HKl reset 0x5 — ADC DRC Limiter Slope High Setting Register
    fields as AC.AC_DAC_DRC_HKl
  0x260 AC_ADC_DRC_LKl reset 0x1EB8 — ADC DRC Limiter Slope Low Setting Register
    fields as AC.AC_DAC_DRC_LKl
  0x264 AC_ADC_DRC_HOPL reset 0xFBD8 — ADC DRC Limiter High Output at Limiter Threshold
    fields as AC.AC_DAC_DRC_HOPL
  0x268 AC_ADC_DRC_LOPL reset 0xFBA7 — ADC DRC Limiter Low Output at Limiter Threshold
    fields as AC.AC_DAC_DRC_HOPL
  0x26C AC_ADC_DRC_HET reset 0xBA0 — ADC DRC Expander Theshold High Setting Register
    fields as AC.AC_DAC_DRC_HET
  0x270 AC_ADC_DRC_LET reset 0x7291 — ADC DRC Expander Theshold Low Setting Register
    fields as AC.AC_DAC_DRC_HET
  0x274 AC_ADC_DRC_HKE reset 0x500 — ADC DRC Expander Slope High Setting Register
    [13:0] EXPANDER_SLOPE — The slope of the expander which determine by the equation that Ke = 1/R, there, R is the ratio of the expander, which always is interger and the ke must larger than 50. The format is 8.24. (1:5)
  0x278 AC_ADC_DRC_LKE — ADC DRC Expander Slope Low Setting Register
    fields as AC.AC_DAC_DRC_LKE
  0x27C AC_ADC_DRC_HOPE reset 0xF45F — ADC DRC Expander High Output at Expander Threshold
    fields as AC.AC_DAC_DRC_HOPE
  0x280 AC_ADC_DRC_LOPE reset 0x8D6E — ADC DRC Expander Low Output at Expander Threshold
    fields as AC.AC_DAC_DRC_HOPE
  0x284 AC_ADC_DRC_HKN reset 0x100 — ADC DRC Linear Slope High Setting Register
    fields as AC.AC_DAC_DRC_HKN
  0x288 AC_ADC_DRC_LKN — ADC DRC Linear Slope Low Setting Register
    fields as AC.AC_DAC_DRC_LKN
  0x28C AC_ADC_DRC_SFHAT reset 0x2 — ADC DRC Smooth filter Gain High Attack Time Coef Register
    fields as AC.AC_DAC_DRC_SFHAT
  0x290 AC_ADC_DRC_SFLAT reset 0x5600 — ADC DRC Smooth filter Gain Low Attack Time Coef Register
    fields as AC.AC_DAC_DRC_SFLAT
  0x294 AC_ADC_DRC_SFHRT — ADC DRC Smooth filter Gain High Release Time Coef Register
    fields as AC.AC_DAC_DRC_SFHRT
  0x298 AC_ADC_DRC_SFLRT reset 0xF04 — ADC DRC Smooth filter Gain Low Release Time Coef Register
    fields as AC.AC_DAC_DRC_SFLRT
  0x29C AC_ADC_DRC_MXGHS reset 0xFE56 — ADC DRC MAX Gain High Setting Register
    fields as AC.AC_DAC_DRC_MXGHS
  0x2A0 AC_ADC_DRC_MXGLS reset 0xCB0F — ADC DRC MIN Gain Low Setting Register
    fields as AC.AC_DAC_DRC_MXGLS
  0x2A8 AC_ADC_DRC_MNGLS reset 0x2C3F — ADC DRC MIN Gain High Setting Register
    fields as AC.AC_DAC_DRC_MNGLS
  0x2AC AC_ADC_DRC_EPSHC — ADC DRC Expander Smooth Time High Coef Register
    [10:0] GAIN_SMOOTH_FILTER_RELEASE — The gain smooth filter release and attack time parameter setting in expander region, which determine by the equation that RT = 1-exp(-2.2Ts/tr). The format is 3.24. (30ms)
  0x2B0 AC_ADC_DRC_EPSLC reset 0x640C — ADC DRC Expander Smooth Time Low Coef Register
    fields as AC.AC_DAC_DRC_EPSLC
  0x2B8 AC_ADC_DRC_HPFHGAIN reset 0x100 — ADC DRC HPF Gain High Coef Register
    fields as AC.AC_DAC_DRC_HPFHGAIN
  0x2BC AC_ADC_DRC_HPFLGAIN — ADC DRC HPF Gain Low Coef Register
    fields as AC.AC_DAC_DRC_HPFLGAIN
0x00 ANALOG DOMAIN REGISTER group
  0x2DE9C0 AC_PR_CFG reset 0x10000000 — AC Parameter Configuration Register
    [28] AC_PR_RST — AC_PR Reset 0: Assert 1: De-assert
      0=Assert; 1=deassert
    [24] AC_PR_RW — AC_PR Read Or Write 0: read 1: write
      0=read; 1=write
    [20:16] AC_PR_ADDR — AC_PR Address [4:0]
    [15:8] ADDA_PR_WDAT — ADDA_PR Write Data [7:0]
    [7:0] ADDA_PR_RDAT — ADDA_PR Read Data [7:0]
0x00 LINEOUT_PA_GAT
  [7] PA — clock gating control; when system VDD is off and Audio analog channel is working, this bit must be set to 1, because the PA clock come from system VDD domain. When this bit is 1, the Zero cross over function will be disabled automatically. 0: not gating; 1: gating
    0=not gating; 1: gating
0x01 LOMIXSC
  [6:0] LMIXMUTE — Left Output Mixer Mute Control 0-Mute, 1-Not Mute Bit 6: MIC1 Boost Stage Bit 5: MIC2 Boost Stage Bit 4: / Bit 3: / Bit 2: LINEINL Bit 1: Left Channel DAC Bit 0: Right Channel DAC
0x02 ROMIXSC
  [6:0] RMIXMUTE — Right Output Mixer Mute Control 0-Mute, 1-Not Mute Bit 6: MIC1 Boost Stage Bit 5: MIC2 Boost Stage Bit 4: / Bit 3: / Bit 2: LINEINR Bit 1: Right Channel DAC Bit 0: Left Channel DAC
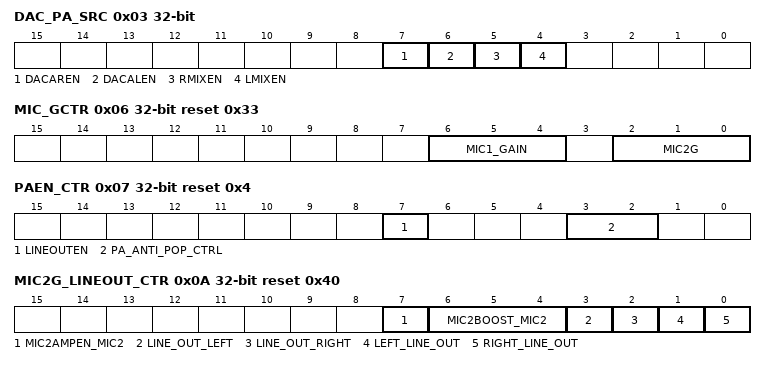
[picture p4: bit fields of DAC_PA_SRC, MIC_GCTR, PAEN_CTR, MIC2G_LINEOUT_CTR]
0x03 DAC_PA_SRC
  [7] DACAREN — Internal Analog Right channel DAC Enable 0:Disable; 1:Enable
  [6] DACALEN — Internal Analog Left channel DAC Enable 0:Disable; 1:Enable
  [5] RMIXEN — Right Analog Output Mixer Enable 0:Disable; 1:Enable
  [4] LMIXEN — Left Analog Output Mixer Enable 0:Disable; 1:Enable
0x05 LINEIN_GCTR reset 0x30
  [6:4] LINEING — LINEING, (volln) LINEINL/R to L/R output mixer Gain Control From -4.5dB to 6dB, 1.5dB/step, default is 0dB
0x06 MIC_GCTR reset 0x33
  [6:4] MIC1_GAIN — MIC1 BOOST stage to L or R output mixer Gain Control From -4.5dB to 6dB, 1.5dB/step, default is 0dB
  [2:0] MIC2G — MIC2G, (volm2) MIC2 BOOST stage to L or R output mixer Gain Control From -4.5dB to 6dB, 1.5dB/step, default is 0dB
0x07 PAEN_CTR reset 0x4
  [7] LINEOUTEN — Right & Left LINEOUT Enable 0-disable 1-enable
  [3:2] PA_ANTI_POP_CTRL — PA_ANTI_POP_CTRL, (slopelengthsel) PA Anti-pop time Control 00:131ms; 01: 262ms; 10: 393ms; 11:524ms
0x09 LINEOUT_VOLC
  [7:3] LINEOUTVOL — Line-out Volume Control, Total 31 level, from 0dB to -48dB, 1.5dB/step, mute when 00000 & 00001
0x0A MIC2G_LINEOUT_CTR reset 0x40
  [7] MIC2AMPEN_MIC2 — MIC2AMPEN MIC2 Boost AMP Enable 0-Disable; 1-Enable
  [6:4] MIC2BOOST_MIC2 — MIC2BOOST MIC2 Boost AMP Gain Control 0dB when 000, 24dB to 42dB when 001 to 111, 3dB/step, default is 33dB
  [3] LINE_OUT_LEFT — Line-out Left Select 0-not select 1-selected
  [2] LINE_OUT_RIGHT — Line-out Right Select 0-not select 1-selected
  [1] LEFT_LINE_OUT — Left line-out source select 0-left output mixer 1-left output mixer + right output mixer
  [0] RIGHT_LINE_OUT — Right line-out source select 0-right output mixer 1-left line-out, for differential output
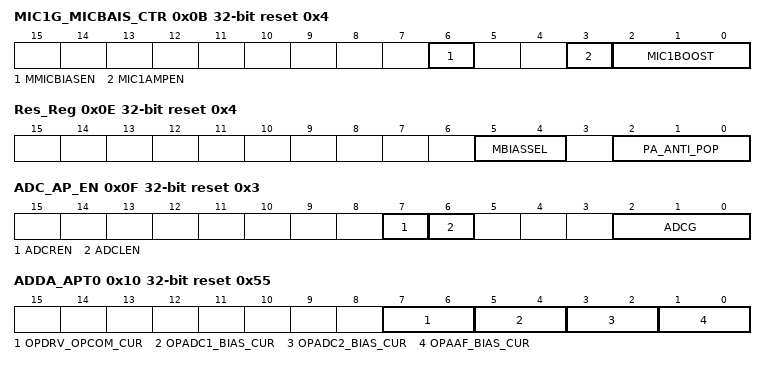
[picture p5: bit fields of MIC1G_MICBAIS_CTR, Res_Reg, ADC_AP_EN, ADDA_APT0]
0x0B MIC1G_MICBAIS_CTR reset 0x4
  [6] MMICBIASEN — Master Microphone Bias enable 0: disable, 1: enable
    0=disable, 1: enable
  [3] MIC1AMPEN — MIC1 Boost AMP Enable 0-Disable; 1-Enable
  [2:0] MIC1BOOST — MIC1 Boost AMP Gain Control 0dB when 000, 24dB to 42dB when 001 to 111, 3dB/step, default is 33dB
0x0C LADCMIXSC
  [6:0] RADCMIXMUTE — Right ADC Mixer Mute Control: 0-Mute, 1-Not Mute Bit 6: MIC1 Boost Stage Bit 5: MIC2 Boost Stage Bit 4: / Bit 3:/ Bit 2: LINEINL Bit 1: Left Output Mixer Bit 0: Right Output Mixer
0x0D RADCMIXSC
  [6:0] RADCMIXMUTE — Right ADC Mixer Mute Control: 0-Mute, 1-Not Mute Bit 6: MIC1 Boost Stage Bit 5: MIC2 Boost Stage Bit 4: / Bit 3:/ Bit 2: LINEINR Bit 1: Right Output Mixer Bit 0: Left Output Mixer
0x0E Res_Reg reset 0x4
  [5:4] MBIASSEL — MMICBIAS voltage level select 00: 1.88V 01: 2.09V 10: 2.33V 11: 2.50V
    0=_1_point_88V (1.88V); 1=_2_point_09V (2.09V); 2=_2_point_33V (2.33V); 3=_2_point_50V (2.50V)
  [2:0] PA_ANTI_POP — PA ANTI-POP Time Control 000: 131ms 001: 262ms 010: 393ms 011: 524ms 100: 655ms 101: 786ms 110: 917ms 111: 1048ms
    0=_131ms; 1=_262ms; 2=_393ms; 3=_524ms; 4=_655ms; 5=_786ms; 6=_917ms; 7=_1048ms
0x0F ADC_AP_EN reset 0x3
  [7] ADCREN — ADC Right Channel Enable 0-Disable; 1-Enable
  [6] ADCLEN — ADC Left Channel Enable 0-Disable; 1-Enable
  [2:0] ADCG — ADC Input Gain Control From -4.5dB to 6dB, 1.5dB/step default is 0dB
0x10 ADDA_APT0 reset 0x55
  [7:6] OPDRV_OPCOM_CUR — OPDRV/OPCOM output stage current setting
  [5:4] OPADC1_BIAS_CUR — OPADC1 Bias Current Select
  [3:2] OPADC2_BIAS_CUR — OPADC2 Bias Current Select
  [1:0] OPAAF_BIAS_CUR — OPAAF in ADC Bias Current Select
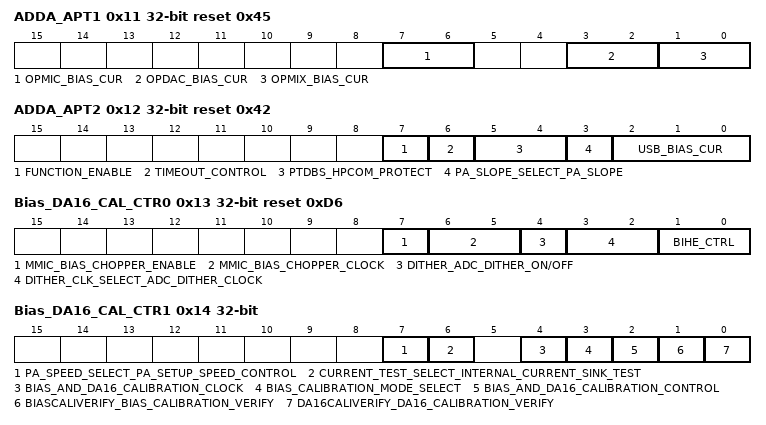
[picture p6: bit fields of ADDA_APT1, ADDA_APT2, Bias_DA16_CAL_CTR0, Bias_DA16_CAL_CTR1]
0x11 ADDA_APT1 reset 0x45
  [7:6] OPMIC_BIAS_CUR — OPMIC Bias Current Control
  [3:2] OPDAC_BIAS_CUR — OPDAC Bias Current Control
  [1:0] OPMIX_BIAS_CUR — OPMIX/OPLPF Bias Current Control
0x12 ADDA_APT2 reset 0x42
  [7] FUNCTION_ENABLE — function enable for master volume change at zero cross over 0: disable; 1: enable
    0=disable; 1=enable
  [6] TIMEOUT_CONTROL — Timeout control for master volume change at zero cross over 0: 32ms; 1: 64ms
    0=_32ms; 1=_64ms
  [5:4] PTDBS_HPCOM_PROTECT — PTDBS HPCOM protect de-bounce time setting 00: 2-3ms; 01: 4-6ms; 10: 8-12ms; 11: 16-24ms at the same time, bit 17 is used to control the AVCCPORFLAG, write 1 to this bit, flag will be clear, and the calibration is done again
    0=_2_minus_3ms (2-3ms; 01: 4-6ms; 10: 8-12ms; 11: 16-24ms at the same time, bit 17 is used to control the AVCCPORFLAG, write 1 to this bit, flag will be clear, and the calibration is done again)
  [3] PA_SLOPE_SELECT_PA_SLOPE — PA_SLOPE_SELECT PA slope select cosine or ramp 0: select cosine 1: select ramp
    0=select_cosine; 1=select_ramp
  [2:0] USB_BIAS_CUR — USB_BIAS_CUR. USB bias current tuning From 23uA to 30uA, Default is 25uA
0x13 Bias_DA16_CAL_CTR0 reset 0xD6
  [7] MMIC_BIAS_CHOPPER_ENABLE — MMIC BIAS chopper enable 0: disable; 1:enable
    0=disable; 1=enable
  [6:5] MMIC_BIAS_CHOPPER_CLOCK — MMIC BIAS chopper clock select 00: 250KHz; 01: 500KHz; 10: 1MHz; 11: 2MHz
    0=_250KHz; 1=_500KHz; 2=_1MHz; 3=_2MHz
  [4] DITHER_ADC_DITHER_ON/OFF — DITHER ADC dither on/off control 0: dither off; 1: dither on
    0=dither_off; 1=dither_on
  [3:2] DITHER_CLK_SELECT_ADC_DITHER_CLOCK — DITHER_CLK_SELECT ADC dither clock select 00: ADC FS * (8/9), about 43KHz when FS=48KHz 01: ADC FS * (16/15), about 51KHz when FS=48KHz 10: ADC FS * (4/3), about 64KHz when FS=48KHz 11: ADC FS * (16/9), about 85KHz when FS=48KHz
    0=ADC_FS__times___openingparen_8_slash_9_closingparen_ (ADC FS * (8/9), about 43KHz when FS=48KHz); 1=ADC_FS__times___openingparen_16_slash_15_closingparen_ (ADC FS * (16/15), about 51KHz when FS=48KHz); 2=ADC_FS__times___openingparen_4_slash_3_closingparen_ (ADC FS * (4/3), about 64KHz when FS=48KHz); 3=ADC_FS__times___openingparen_16_slash_9_closingparen_ (ADC FS * (16/9), about 85KHz when FS=48KHz)
  [1:0] BIHE_CTRL — BIHE_CTRL, BIHE control 00: no BIHE 01: BIHE=7.5 HOSC 10: BIHE=11.5 HOSC 11: BIHE=15.5 HOSC
    0=no_BIHE; 1=BIHE_equals_7_point_5 (BIHE=7.5 HOSC); 2=BIHE_equals_11_point_5 (BIHE=11.5 HOSC); 3=BIHE_equals_15_point_5 (BIHE=15.5 HOSC)
0x14 Bias_DA16_CAL_CTR1
  [7] PA_SPEED_SELECT_PA_SETUP_SPEED_CONTROL — PA_SPEED_SELECT PA setup speed control (for testing) 0: slow; 1: fast
    0=slow; 1: fast
  [6] CURRENT_TEST_SELECT_INTERNAL_CURRENT_SINK_TEST — CURRENT_TEST_SELECT Internal current sink test enable (from LINEIN pin) 0:Normal; 1: For Debug
  [4] BIAS_AND_DA16_CALIBRATION_CLOCK — BIAS and DA16 calibration clock select 0: 1KHz; 1: 500Hz
    0=_1KHz; 1=_500Hz
  [3] BIAS_CALIBRATION_MODE_SELECT — BIAS calibration mode select 0: average; 1: single
    0=average; 1=single
  [2] BIAS_AND_DA16_CALIBRATION_CONTROL — BIAS and DA16 calibration control Write 1 to this bit, the calibration will be doing again. Then this bit will be reset to zero automatically
  [1] BIASCALIVERIFY_BIAS_CALIBRATION_VERIFY — BIASCALIVERIFY Bias Calibration Verify 0: Calibration; 1: Register setting
    0=Calibration; 1: Register setting
  [0] DA16CALIVERIFY_DA16_CALIBRATION_VERIFY — DA16CALIVERIFY DA16 Calibration Verify 0: Calibration; 1: Register setting
    0=Calibration; 1: Register setting
0x15 DA16CALI reset 0x80
  [7:0] DA16CALI ro — DA16 Calibration Data
0x16 DA16VERIFY reset 0x80 (reset mask 0xFF)
0x17 BIASCALI reset 0x20
  [7:0] BIASCALI ro — Bias Calibration Data, 6bit
0x18 BIASVERIFY reset 0x20
  [7:0] BIASVERIFY — Bias Register Setting Data, 6bit
0x98 AC_ADC_DAP_RNAC reset 0x51EB8
  [26:0] ADAP_RINAC — Right input signal average filter coefficient to check noise or not (the coefficientis 3.24 format 2s complement) always the same as the left output signal average filter's
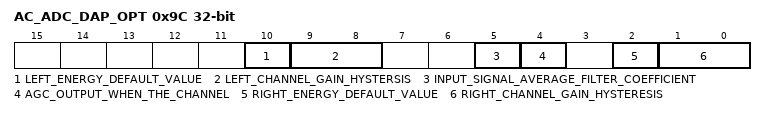
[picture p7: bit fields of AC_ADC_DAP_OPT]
0x9C AC_ADC_DAP_OPT
  [10] LEFT_ENERGY_DEFAULT_VALUE — Left energy default value setting (include the input and output) 0 : min 1 : max
  [9:8] LEFT_CHANNEL_GAIN_HYSTERSIS — Left channel gain hystersis setting. The different between target level and the signal level must larger than the hystersis when the gain change. 00 : 0.4375db 01 : 0.9375db 10 : 1.9375db 11 : 3db
  [5] INPUT_SIGNAL_AVERAGE_FILTER_COEFFICIENT — The input signal average filter coefficient setting 0 : is the reg94/reg98 1 : is the reg80/reg88;
  [4] AGC_OUTPUT_WHEN_THE_CHANNEL — AGC output when the channel in noise state 0 : output is zero 1 : output is the input data
  [2] RIGHT_ENERGY_DEFAULT_VALUE — Right energy default value setting (include the input and output) 0 : min 1 : max
  [1:0] RIGHT_CHANNEL_GAIN_HYSTERESIS — Right channel gain hysteresis setting. The different between target level and the signal level must larger than the hysteresis when the gain change. 00 : 0.4375db 01 : 0.9375db 10 : 1.9375db 11 : 3db
0x2A4 AC_ADC_DRC_MNGHS reset 0xF95B
  fields as AC.AC_DAC_DRC_MNGHS
